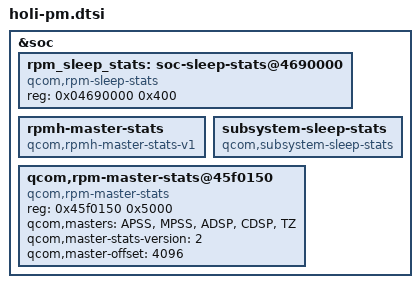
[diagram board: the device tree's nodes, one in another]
&soc {
	rpm_sleep_stats: soc-sleep-stats@4690000 {
		compatible = "qcom,rpm-sleep-stats";
		reg = <0x04690000 0x400>;
	};

	rpmh-master-stats {
		compatible = "qcom,rpmh-master-stats-v1";
	};

	subsystem-sleep-stats {
		compatible = "qcom,subsystem-sleep-stats";
	};

	qcom,rpm-master-stats@45f0150 {
		compatible = "qcom,rpm-master-stats";
		reg = <0x45f0150 0x5000>;
		qcom,masters = "APSS", "MPSS", "ADSP", "CDSP", "TZ";
		qcom,master-stats-version = <2>;
		qcom,master-offset = <4096>;
	};
};
